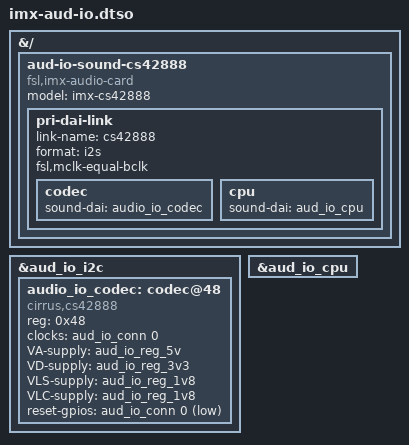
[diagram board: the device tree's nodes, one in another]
// SPDX-License-Identifier: (GPL-2.0+ OR MIT)
/*
 * Common Device Tree for the IMX-AUD-IO daughter board[1].
 * It connects to the baseboard through a PCIe X8 slot.
 *
 * [1]https://www.nxp.com/part/IMX-AUD-IO
 *
 * Copyright 2026 NXP
 */

/dts-v1/;
/plugin/;

#include <dt-bindings/gpio/gpio.h>

&{/} {
	aud-io-sound-cs42888 {
		compatible = "fsl,imx-audio-card";
		model = "imx-cs42888";

		pri-dai-link {
			link-name = "cs42888";
			format = "i2s";
			fsl,mclk-equal-bclk;

			codec {
				sound-dai = <&audio_io_codec>;
			};

			cpu {
				sound-dai = <&aud_io_cpu>;
			};

		};
	};
};

&aud_io_i2c {
	#address-cells = <1>;
	#size-cells = <0>;

	audio_io_codec: codec@48 {
		compatible = "cirrus,cs42888";
		reg = <0x48>;
		clocks = <&aud_io_conn 0>;
		clock-names = "mclk";
		VA-supply = <&aud_io_reg_5v>;
		VD-supply = <&aud_io_reg_3v3>;
		VLS-supply = <&aud_io_reg_1v8>;
		VLC-supply = <&aud_io_reg_1v8>;
		#sound-dai-cells = <0>;
		reset-gpios = <&aud_io_conn 0 GPIO_ACTIVE_LOW>;
	};
};

&aud_io_cpu {
	status = "okay";
};
